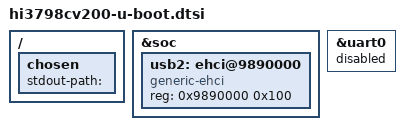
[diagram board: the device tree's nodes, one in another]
// SPDX-License-Identifier: GPL-2.0+
/*
 * U-Boot addition to:
 *  1) use platform data for the console
 *  2) provide support for the generic-ehci USB driver currently not available
 *     in the linux kernel (8/May/2017).
 *
 * (C) Copyright 2017 Jorge Ramirez-Ortiz <jorge.ramirez-ortiz@linaro.org>
 */

&soc {
	usb2: ehci@9890000 {
		compatible = "generic-ehci";
		reg = <0x9890000 0x100>;
		status = "okay";
	};
};

&uart0 {
	status = "disabled";
};

/{
	chosen {
		stdout-path = "";
	};
};

